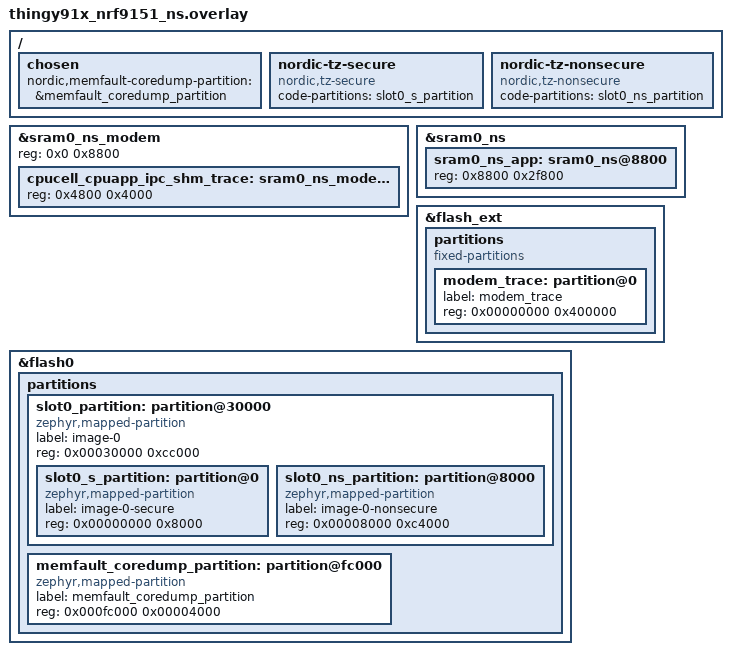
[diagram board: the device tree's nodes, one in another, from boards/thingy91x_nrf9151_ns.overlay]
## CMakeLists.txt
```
#
# Copyright (c) 2021 Nordic Semiconductor
#
# SPDX-License-Identifier: LicenseRef-Nordic-5-Clause
#

cmake_minimum_required(VERSION 3.20.0)

find_package(Zephyr REQUIRED HINTS $ENV{ZEPHYR_BASE})
project(memfault_sample)

# NORDIC SDK APP START
add_subdirectory(src)
# NORDIC SDK APP END

zephyr_include_directories(src)
zephyr_include_directories(config)
```

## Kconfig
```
#
# Copyright (c) 2021 Nordic Semiconductor ASA
#
# SPDX-License-Identifier: LicenseRef-Nordic-5-Clause
#

menu "Zephyr Kernel"
source "Kconfig.zephyr"
endmenu

module = MEMFAULT_SAMPLE
module-str = Memfault sample
source "$(ZEPHYR_BASE)/subsys/logging/Kconfig.template.log_config"
```

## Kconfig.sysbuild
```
#
# Copyright (c) 2024 Nordic Semiconductor
#
# SPDX-License-Identifier: LicenseRef-Nordic-5-Clause
#

config WIFI_NRF70
	default y if BOARD_NRF7002DK_NRF5340_CPUAPP

source "share/sysbuild/Kconfig"
```

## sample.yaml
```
sample:
  name: Memfault sample
tests:
  sample.debug.memfault:
    sysbuild: true
    build_only: true
    extra_configs:
      - CONFIG_MEMFAULT_NCS_PROJECT_KEY="dummy-key"
    integration_platforms:
      - nrf9151dk/nrf9151/ns
      - thingy91x/nrf9151/ns
      - nrf7002dk/nrf5340/cpuapp
    platform_allow:
      - nrf9160dk/nrf9160/ns
      - nrf9161dk/nrf9161/ns
      - nrf9151dk/nrf9151/ns
      - thingy91/nrf9160/ns
      - thingy91x/nrf9151/ns
      - nrf7002dk/nrf5340/cpuapp
    tags:
      - ci_build
      - sysbuild
      - ci_samples_debug
  sample.debug.memfault.etb:
    sysbuild: true
    build_only: true
    extra_configs:
      - CONFIG_MEMFAULT_NCS_PROJECT_KEY="dummy-key"
    extra_args: OVERLAY_CONFIG=overlay-etb.conf
    integration_platforms:
      - nrf9161dk/nrf9161/ns
      - nrf9151dk/nrf9151/ns
      - thingy91x/nrf9151/ns
    platform_allow:
      - nrf9160dk/nrf9160/ns
      - nrf9161dk/nrf9161/ns
      - nrf9151dk/nrf9151/ns
      - thingy91/nrf9160/ns
      - thingy91x/nrf9151/ns
    tags:
      - ci_build
      - sysbuild
      - ci_samples_debug
  # Split off from sample.debug.memfault.etb: ETB_TRACE depends on
  # SOC_SERIES_NRF91, so on the nRF5340 the whole ETB part of overlay-etb.conf
  # was silently dropped. This variant uses an overlay without it.
  sample.debug.memfault.etb.nrf53:
    sysbuild: true
    build_only: true
    extra_configs:
      - CONFIG_MEMFAULT_NCS_PROJECT_KEY="dummy-key"
    extra_args: OVERLAY_CONFIG=overlay-etb-nrf53.conf
    integration_platforms:
      - nrf7002dk/nrf5340/cpuapp
    platform_allow:
      - nrf7002dk/nrf5340/cpuapp
    tags:
      - ci_build
      - sysbuild
      - ci_samples_debug
  sample.debug.memfault.modem_trace_to_memfault:
    sysbuild: true
    build_only: true
    extra_configs:
      - CONFIG_MEMFAULT_NCS_PROJECT_KEY="dummy-key"
    extra_args: OVERLAY_CONFIG=overlay-modem-trace-to-memfault.conf
    integration_platforms:
      - nrf9151dk/nrf9151/ns
      - thingy91x/nrf9151/ns
    platform_allow:
      - nrf9151dk/nrf9151/ns
      - thingy91x/nrf9151/ns
    tags:
      - ci_build
      - sysbuild
      - ci_samples_debug
```

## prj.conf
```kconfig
#
# Copyright (c) 2021 Nordic Semiconductor ASA
#
# SPDX-License-Identifier: LicenseRef-Nordic-5-Clause
#

# General config
CONFIG_FPU=y
CONFIG_ASSERT=y

# Logging
CONFIG_LOG=y
CONFIG_LOG_BUFFER_SIZE=4096

# For more verbose and detailed log output, set the log level to
# CONFIG_MEMFAULT_SAMPLE_LOG_LEVEL_DBG=y instead.
CONFIG_MEMFAULT_SAMPLE_LOG_LEVEL_INF=y

# Network
CONFIG_NETWORKING=y
CONFIG_NET_NATIVE=y
CONFIG_NET_IPV4=y
CONFIG_NET_CONNECTION_MANAGER=y

# DK
CONFIG_DK_LIBRARY=y

# Memfault
CONFIG_MEMFAULT=y
CONFIG_MEMFAULT_PROJECT_KEY=""
CONFIG_MEMFAULT_SHELL=y
CONFIG_MEMFAULT_HTTP_PERIODIC_UPLOAD=y
CONFIG_MEMFAULT_LOGGING_ENABLE=y
CONFIG_MEMFAULT_LOGGING_RAM_SIZE=4096
CONFIG_MEMFAULT_LOG_LEVEL_DBG=y
CONFIG_MEMFAULT_NCS_STACK_METRICS=y
CONFIG_MEMFAULT_COREDUMP_FULL_THREAD_STACKS=y
CONFIG_MEMFAULT_HEAP_STATS=y

# Add to pick up support for sending Memfault data over HTTP
CONFIG_MEMFAULT_HTTP_ENABLE=y

# Store coredump to flash
CONFIG_MEMFAULT_NCS_LOG_LEVEL_DBG=y
CONFIG_MEMFAULT_NCS_INTERNAL_FLASH_BACKED_COREDUMP=y
CONFIG_MEMFAULT_COREDUMP_COLLECT_BSS_REGIONS=y

# Dependency for Memfaul shell
CONFIG_SHELL=y

# Dependencies for flash storage
CONFIG_FLASH=y
CONFIG_FLASH_MAP=y
CONFIG_STREAM_FLASH=y

# Heap and stacks
CONFIG_HEAP_MEM_POOL_SIZE=8192
CONFIG_MAIN_STACK_SIZE=8192
CONFIG_SYSTEM_WORKQUEUE_STACK_SIZE=2048
CONFIG_NET_CONNECTION_MANAGER_MONITOR_STACK_SIZE=1024
CONFIG_NET_MGMT_EVENT_STACK_SIZE=1024

# Memfault depends on POSIX, disable unneeded POSIX features
CONFIG_POSIX_FILE_SYSTEM=n
```

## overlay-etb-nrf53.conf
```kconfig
#
# Copyright (c) 2023 Nordic Semiconductor ASA
#
# SPDX-License-Identifier: LicenseRef-Nordic-5-Clause
#

# Variant of overlay-etb.conf for SoCs without an ETB. ETB_TRACE depends on
# SOC_SERIES_NRF91, and ETB_TRACE_LOW_POWER and MEMFAULT_NCS_ETB_CAPTURE depend
# on ETB_TRACE in turn, so those three settings cannot be applied here. Only the
# logging reduction is kept so the build stays comparable to the nRF91 one.
CONFIG_FAULT_DUMP=0
CONFIG_KERNEL_LOG_LEVEL_OFF=y
```

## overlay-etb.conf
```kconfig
#
# Copyright (c) 2023 Nordic Semiconductor ASA
#
# SPDX-License-Identifier: LicenseRef-Nordic-5-Clause
#

# ETB tracing
CONFIG_ETB_TRACE=y
CONFIG_ETB_TRACE_LOW_POWER=y
CONFIG_MEMFAULT_NCS_ETB_CAPTURE=y
# Reduce logging to avoid filling up ETB with data not related to the crash
CONFIG_FAULT_DUMP=0
CONFIG_KERNEL_LOG_LEVEL_OFF=y
```

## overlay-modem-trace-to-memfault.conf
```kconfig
#
# Copyright (c) 2025 Nordic Semiconductor ASA
#
# SPDX-License-Identifier: LicenseRef-Nordic-5-Clause
#

# Continuously store modem traces to flash and upload them to Memfault upon a coredump

# Memfault
CONFIG_MEMFAULT_NCS_POST_MODEM_TRACE_ON_COREDUMP=y

# nRF Modem lib trace
CONFIG_FCB=y
CONFIG_FLASH_MAP=y
CONFIG_NRF_MODEM_LIB_TRACE=y
# Set the default trace level to off preventing overwriting the trace leading up to the crash after
# boot. The Memfault LTE coredump modem trace layer will ensure that traces are enabled once
# the coredump/modem trace has been uploaded, or if there is no application coredump.
CONFIG_NRF_MODEM_LIB_TRACE_LEVEL_OFF=y
CONFIG_NRF_MODEM_LIB_SHELL_TRACE=y
CONFIG_NRF_MODEM_LIB_TRACE_BACKEND_FLASH=y
CONFIG_NRF_MODEM_TRACE_FLASH_NOSPACE_ERASE_OLDEST=y
CONFIG_NRF_MODEM_LIB_TRACE_STACK_SIZE=1024
# Maximum number of sectors that the trace backend can handle
CONFIG_NRF_MODEM_LIB_TRACE_FLASH_SECTORS=255
# Modem trace flash partition size with 255 sectors of 4kB each
CONFIG_NRF_MODEM_LIB_TRACE_BACKEND_FLASH_PARTITION_SIZE=0xFF000
```

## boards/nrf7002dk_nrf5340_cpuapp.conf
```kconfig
#
# Copyright (c) 2023 Nordic Semiconductor ASA
#
# SPDX-License-Identifier: LicenseRef-Nordic-5-Clause
#

# General
CONFIG_POSIX_TIMERS=y
CONFIG_HW_STACK_PROTECTION=y
CONFIG_HW_ID_LIBRARY=y
CONFIG_HW_ID_LIBRARY_SOURCE_NET_MAC=y

# Heap and stacks
CONFIG_HEAP_MEM_POOL_SIZE=153600
CONFIG_HEAP_MEM_POOL_SIZE=40144
CONFIG_NRF_WIFI_CTRL_HEAP_SIZE=15000
CONFIG_NRF_WIFI_DATA_HEAP_SIZE=98456
CONFIG_HEAP_MEM_POOL_IGNORE_MIN=y
CONFIG_SYSTEM_WORKQUEUE_STACK_SIZE=4096
CONFIG_MAIN_STACK_SIZE=8192
CONFIG_NET_TX_STACK_SIZE=4096
CONFIG_NET_RX_STACK_SIZE=4096
CONFIG_NET_CONNECTION_MANAGER_MONITOR_STACK_SIZE=4096

# Network and NET sockets
CONFIG_NET_L2_ETHERNET=y
CONFIG_NET_TCP=y
CONFIG_NET_UDP=y
CONFIG_NET_DHCPV4=y
CONFIG_NET_SOCKETS_OFFLOAD=n
CONFIG_NET_CONTEXT_SNDTIMEO=y
CONFIG_NET_CONTEXT_SYNC_RECV=y
CONFIG_NET_SOCKETS_ENABLE_DTLS=n
CONFIG_NET_SOCKETS_SOCKOPT_TLS=y
CONFIG_NET_SOCKETS=y
CONFIG_ZVFS_POLL_MAX=20
CONFIG_NET_STATISTICS=y
CONFIG_NET_STATISTICS_WIFI=y
CONFIG_NET_STATISTICS_USER_API=y
CONFIG_NET_PKT_RX_COUNT=8
CONFIG_NET_PKT_TX_COUNT=8
CONFIG_NET_MAX_CONTEXTS=5

# DNS
CONFIG_DNS_RESOLVER=y
CONFIG_NET_SOCKETS_DNS_TIMEOUT=30000

# printing of scan results puts pressure on queues in new locking
# design in net_mgmt. So, use a typical number of networks in a crowded
# environment as the queue depth.
CONFIG_NET_MGMT_EVENT_QUEUE_SIZE=150
CONFIG_NET_MGMT_EVENT_STACK_SIZE=4096

# Below section is the primary contributor to SRAM and is currently
# not optimized for size.
CONFIG_NET_BUF_RX_COUNT=16
CONFIG_NET_BUF_TX_COUNT=64
CONFIG_NET_BUF_DATA_SIZE=128
CONFIG_NET_TC_TX_COUNT=1

# Wi-Fi
CONFIG_WIFI=y
CONFIG_WIFI_NRF70=y
CONFIG_NET_L2_WIFI_SHELL=y
CONFIG_NET_SHELL=y
CONFIG_WIFI_CREDENTIALS=y

# Shell
CONFIG_SHELL=y
CONFIG_SHELL_STACK_SIZE=6144

# WPA
CONFIG_WIFI_NM_WPA_SUPPLICANT=y
CONFIG_WIFI_NM_WPA_SUPPLICANT_LOG_LEVEL_INF=y

# Settings subsystem
CONFIG_NVS=y
CONFIG_SETTINGS=y
CONFIG_SETTINGS_NVS=y

# mbedTLS
CONFIG_PSA_CRYPTO=y
CONFIG_MBEDTLS=y
CONFIG_MBEDTLS_ENABLE_HEAP=y
CONFIG_MBEDTLS_HEAP_SIZE=81920

# Memfault servers negotiate ECDHE-RSA when using MbedTLS 4.0
CONFIG_MBEDTLS_CIPHERSUITE_TLS_ECDHE_RSA_WITH_AES_128_GCM_SHA256=y
CONFIG_MBEDTLS_SSL_SERVER_NAME_INDICATION=y

# Certificate management
CONFIG_MEMFAULT_ROOT_CERT_STORAGE_TLS_CREDENTIAL_STORAGE=y
CONFIG_MEMFAULT_NCS_PROVISION_CERTIFICATES=y

# Zephyr NET Connection Manager Connectivity layer.
CONFIG_L2_WIFI_CONNECTIVITY=y
CONFIG_L2_WIFI_CONNECTIVITY_AUTO_CONNECT=n
CONFIG_L2_WIFI_CONNECTIVITY_AUTO_DOWN=n
```

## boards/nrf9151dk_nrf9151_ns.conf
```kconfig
#
# Copyright (c) 2024 Nordic Semiconductor ASA
#
# SPDX-License-Identifier: LicenseRef-Nordic-5-Clause
#

# TF-M
CONFIG_TFM_PROFILE_TYPE_MINIMAL=y

# Network
CONFIG_NET_SOCKETS=y
CONFIG_NET_SOCKETS_OFFLOAD=y

# Memfault
CONFIG_MEMFAULT_NCS_LTE_METRICS=y
CONFIG_MEMFAULT_NCS_POST_COREDUMP_ON_NETWORK_CONNECTED=y
CONFIG_LTE_LC_EDRX_MODULE=y
CONFIG_LTE_LC_PSM_MODULE=y

CONFIG_HW_ID_LIBRARY_SOURCE_IMEI=y
CONFIG_MODEM_INFO=y

# Certificate management
CONFIG_MEMFAULT_ROOT_CERT_STORAGE_NRF9160_MODEM=y
CONFIG_MODEM_KEY_MGMT=y

# AT command capability in shell
CONFIG_AT_SHELL=y
CONFIG_SHELL_WILDCARD=n

# Zephyr NET Connection Manager and Connectivity layer.
CONFIG_NRF_MODEM_LIB_NET_IF=y

# Disable Duplicate Address Detection (DAD)
# due to not being properly implemented for offloaded interfaces.
CONFIG_NET_IPV6_NBR_CACHE=n
CONFIG_NET_IPV6_MLD=n

# Enable SPI for External flash for storing modem traces that are uploaded to Memfault
CONFIG_SPI=y
CONFIG_SPI_NOR=y
CONFIG_SPI_NOR_SFDP_DEVICETREE=y
```

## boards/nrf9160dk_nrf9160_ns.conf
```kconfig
#
# Copyright (c) 2023 Nordic Semiconductor ASA
#
# SPDX-License-Identifier: LicenseRef-Nordic-5-Clause
#

# Network
CONFIG_NET_SOCKETS=y
CONFIG_NET_SOCKETS_OFFLOAD=y

# Memfault
CONFIG_MEMFAULT_NCS_LTE_METRICS=y
CONFIG_MEMFAULT_NCS_POST_COREDUMP_ON_NETWORK_CONNECTED=y
CONFIG_LTE_LC_EDRX_MODULE=y
CONFIG_LTE_LC_PSM_MODULE=y

CONFIG_HW_ID_LIBRARY_SOURCE_IMEI=y
CONFIG_MODEM_INFO=y

# Certificate management
CONFIG_MEMFAULT_ROOT_CERT_STORAGE_NRF9160_MODEM=y
CONFIG_MODEM_KEY_MGMT=y

# AT command capability in shell
CONFIG_AT_SHELL=y
CONFIG_SHELL_WILDCARD=n

# Zephyr NET Connection Manager and Connectivity layer.
CONFIG_NRF_MODEM_LIB_NET_IF=y

# Disable Duplicate Address Detection (DAD)
# due to not being properly implemented for offloaded interfaces.
CONFIG_NET_IPV6_NBR_CACHE=n
CONFIG_NET_IPV6_MLD=n
```

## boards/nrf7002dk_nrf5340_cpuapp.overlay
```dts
/*
 * Copyright (c) 2026 Nordic Semiconductor ASA
 *
 * SPDX-License-Identifier: LicenseRef-Nordic-5-Clause
 */

/ {
	chosen {
		nordic,memfault-coredump-partition = &memfault_coredump_partition;
	};
};

/delete-node/ &storage_partition;

&flash0 {
	partitions {
		storage_partition: partition@f8000 {
			compatible = "zephyr,mapped-partition";
			label = "storage";
			reg = <0x000f8000 0x00004000>;
		};

		memfault_coredump_partition: partition@fc000 {
			compatible = "zephyr,mapped-partition";
			label = "memfault_coredump_partition";
			reg = <0x000fc000 0x00004000>;
		};
	};
};
```

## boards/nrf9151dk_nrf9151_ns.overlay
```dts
/*
 * Copyright (c) 2025 Nordic Semiconductor ASA
 *
 * SPDX-License-Identifier: LicenseRef-Nordic-5-Clause
 */

#include <samples/cellular/nrf91_no_bootloader_partitions.dtsi>

#include <samples/cellular/nrf91_sram_partitions.dtsi>

/* Increase modem (shared) memory. */
&sram0_ns_modem {
	reg = <0x0 0x8800>;
	ranges = <0x0 0x0 0x8800>;

	cpucell_cpuapp_ipc_shm_trace: sram0_ns_modem@4800 {
		/* Modem trace memory */
		reg = <0x4800 0x4000>;
	};
};

/* Delete Non-Secure application memory so we can move and shrink it. */
/delete-node/ &sram0_ns_app;

&sram0_ns {
	sram0_ns_app: sram0_ns@8800 {
		/* Redefine smaller Non-Secure application memory. */
		reg = <0x8800 0x2f800>;
	};
};

&gd25wb256 {
	status = "okay";

	partitions {
		compatible = "fixed-partitions";
		#address-cells = <1>;
		#size-cells = <1>;

		modem_trace: partition@0 {
			label = "modem_trace";
			reg = <0x00000000 0x400000>;
		};
	};
};

/* The internal-flash coredump backend (CONFIG_MEMFAULT_NCS_INTERNAL_FLASH_BACKED_COREDUMP)
 * memory-maps the coredump partition and reads it with memcpy(), so it must live in
 * internal flash (not on the external gd25wb256). Carve it out of the storage region.
 */
/delete-node/ &storage_partition;

&flash0 {
	partitions {
		storage_partition: partition@f8000 {
			compatible = "zephyr,mapped-partition";
			label = "storage";
			reg = <0x000f8000 0x00004000>;
		};

		memfault_coredump_partition: partition@fc000 {
			compatible = "zephyr,mapped-partition";
			label = "memfault_coredump_partition";
			reg = <0x000fc000 0x00004000>;
		};
	};
};

/ {
	chosen {
		nordic,memfault-coredump-partition = &memfault_coredump_partition;
	};
};

/*
 * This layout redefines the flash partition map, dropping partitions that the
 * upstream nordic-tz-secure/-nonsecure descriptors reference. Remove the
 * descriptors so they do not hold dangling phandles (restores the behaviour
 * from before the descriptors were introduced).
 */
/ {
	/delete-node/ nordic-tz-secure;
	/delete-node/ nordic-tz-nonsecure;
};
```

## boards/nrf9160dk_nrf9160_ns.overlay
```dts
/*
 * Copyright (c) 2026 Nordic Semiconductor ASA
 *
 * SPDX-License-Identifier: LicenseRef-Nordic-5-Clause
 */

#include <samples/cellular/nrf91_no_bootloader_partitions.dtsi>

#include <samples/cellular/nrf91_sram_partitions.dtsi>

/* The internal-flash coredump backend (CONFIG_MEMFAULT_NCS_INTERNAL_FLASH_BACKED_COREDUMP)
 * memory-maps the coredump partition and reads it with memcpy(), so it must live in
 * internal flash (not on the external mx25r64). Carve it out of the storage region.
 */
/delete-node/ &storage_partition;

&flash0 {
	partitions {
		storage_partition: partition@f8000 {
			compatible = "zephyr,mapped-partition";
			label = "storage";
			reg = <0x000f8000 0x00004000>;
		};

		memfault_coredump_partition: partition@fc000 {
			compatible = "zephyr,mapped-partition";
			label = "memfault_coredump_partition";
			reg = <0x000fc000 0x00004000>;
		};
	};
};

/ {
	chosen {
		nordic,memfault-coredump-partition = &memfault_coredump_partition;
	};
};
```

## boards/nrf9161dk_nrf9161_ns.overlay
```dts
/*
 * Copyright (c) 2026 Nordic Semiconductor ASA
 *
 * SPDX-License-Identifier: LicenseRef-Nordic-5-Clause
 */

#include <samples/cellular/nrf91_no_bootloader_partitions.dtsi>

#include <samples/cellular/nrf91_sram_partitions.dtsi>

/* The internal-flash coredump backend (CONFIG_MEMFAULT_NCS_INTERNAL_FLASH_BACKED_COREDUMP)
 * memory-maps the coredump partition and reads it with memcpy(), so it must live in
 * internal flash (not on the external gd25wb256). Carve it out of the storage region.
 */
/delete-node/ &storage_partition;

&flash0 {
	partitions {
		storage_partition: partition@f8000 {
			compatible = "zephyr,mapped-partition";
			label = "storage";
			reg = <0x000f8000 0x00004000>;
		};

		memfault_coredump_partition: partition@fc000 {
			compatible = "zephyr,mapped-partition";
			label = "memfault_coredump_partition";
			reg = <0x000fc000 0x00004000>;
		};
	};
};

/ {
	chosen {
		nordic,memfault-coredump-partition = &memfault_coredump_partition;
	};
};

/*
 * This layout redefines the flash partition map, dropping partitions that the
 * upstream nordic-tz-secure/-nonsecure descriptors reference. Remove the
 * descriptors so they do not hold dangling phandles (restores the behaviour
 * from before the descriptors were introduced).
 */
/ {
	/delete-node/ nordic-tz-secure;
	/delete-node/ nordic-tz-nonsecure;
};
```

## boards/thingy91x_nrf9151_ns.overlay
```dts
/*
 * Copyright (c) 2025 Nordic Semiconductor ASA
 *
 * SPDX-License-Identifier: LicenseRef-Nordic-5-Clause
 */

/ {
	chosen {
		nordic,memfault-coredump-partition = &memfault_coredump_partition;
	};
};

/* Increase modem (shared) memory to add trace section. */
&sram0_ns_modem {
	reg = <0x0 0x8800>;
	ranges = <0x0 0x0 0x8800>;

	cpucell_cpuapp_ipc_shm_trace: sram0_ns_modem@4800 {
		/* Modem trace memory */
		reg = <0x4800 0x4000>;
	};
};

/* Delete Non-Secure application memory so we can move and shrink it. */
/delete-node/ &sram0_ns_app;

&sram0_ns {
	sram0_ns_app: sram0_ns@8800 {
		/* Redefine smaller Non-Secure application memory. */
		reg = <0x8800 0x2f800>;
	};
};

&flash_ext {
	partitions {
		compatible = "fixed-partitions";
		#address-cells = <1>;
		#size-cells = <1>;

		modem_trace: partition@0 {
			label = "modem_trace";
			reg = <0x00000000 0x400000>;
		};
	};
};

/* The internal-flash coredump backend (CONFIG_MEMFAULT_NCS_INTERNAL_FLASH_BACKED_COREDUMP)
 * memory-maps the coredump partition and reads it with memcpy(), so it must live in
 * internal flash (not on the external flash_ext). The internal flash is fully consumed
 * by slot0_partition, so shrink the non-secure image area by 16 kB to free space for the
 * coredump partition at the end of internal flash (mirrors the memfault-coredump snippet).
 */
/delete-node/ &slot0_partition;

&flash0 {
	partitions {
		slot0_partition: partition@30000 {
			compatible = "zephyr,mapped-partition";
			label = "image-0";
			reg = <0x00030000 0xcc000>;
			ranges = <0x0 0x00030000 0xcc000>;
			#address-cells = <1>;
			#size-cells = <1>;

			slot0_s_partition: partition@0 {
				compatible = "zephyr,mapped-partition";
				label = "image-0-secure";
				reg = <0x00000000 0x8000>;
			};

			slot0_ns_partition: partition@8000 {
				compatible = "zephyr,mapped-partition";
				label = "image-0-nonsecure";
				reg = <0x00008000 0xc4000>;
			};
		};

		memfault_coredump_partition: partition@fc000 {
			compatible = "zephyr,mapped-partition";
			label = "memfault_coredump_partition";
			reg = <0x000fc000 0x00004000>;
		};
	};
};

/ {
	/delete-node/ nordic-tz-secure;
	/delete-node/ nordic-tz-nonsecure;

	nordic-tz-secure {
		compatible = "nordic,tz-secure";
		code-partitions = <&slot0_s_partition>;
	};

	nordic-tz-nonsecure {
		compatible = "nordic,tz-nonsecure";
		code-partitions = <&slot0_ns_partition>;
	};
};
```

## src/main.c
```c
/*
 * Copyright (c) 2021 Nordic Semiconductor ASA
 *
 * SPDX-License-Identifier: LicenseRef-Nordic-5-Clause
 */

#include <zephyr/kernel.h>
#include <stdio.h>
#include <zephyr/net/conn_mgr_connectivity.h>
#include <zephyr/net/conn_mgr_monitor.h>
#include <memfault/metrics/metrics.h>
#include <memfault/ports/zephyr/http.h>
#include <memfault/core/data_packetizer.h>
#include <memfault/core/trace_event.h>
#include <memfault/panics/coredump.h>
#include <dk_buttons_and_leds.h>

#include <zephyr/logging/log.h>
#include <zephyr/logging/log_ctrl.h>

LOG_MODULE_REGISTER(memfault_sample, CONFIG_MEMFAULT_SAMPLE_LOG_LEVEL);

/* Macros used to subscribe to specific Zephyr NET management events. */
#define L4_EVENT_MASK	      (NET_EVENT_L4_CONNECTED | NET_EVENT_L4_DISCONNECTED)
#define CONN_LAYER_EVENT_MASK (NET_EVENT_CONN_IF_FATAL_ERROR)

static K_SEM_DEFINE(nw_connected_sem, 0, 1);

/* Zephyr NET management event callback structures. */
static struct net_mgmt_event_callback l4_cb;
static struct net_mgmt_event_callback conn_cb;

/* Recursive Fibonacci calculation used to trigger stack overflow. */
static int fib(int n)
{
	if (n <= 1) {
		return n;
	}

	return fib(n - 1) + fib(n - 2);
}

/* Handle button presses and trigger faults that can be captured and sent to
 * the Memfault cloud for inspection after rebooting:
 * Only button 1 is available on Thingy:91, the rest are available on nRF9160 DK.
 *	Button 1: Trigger stack overflow.
 *	Button 2: Trigger NULL-pointer dereference.
 *	Switch 1: Increment switch_1_toggle_count metric by one.
 *	Switch 2: Trace switch_2_toggled event, along with switch state.
 */
static void button_handler(uint32_t button_states, uint32_t has_changed)
{
	uint32_t buttons_pressed = has_changed & button_states;

	if (buttons_pressed & DK_BTN1_MSK) {
		LOG_WRN("Stack overflow will now be triggered");
		fib(10000);
	} else if (buttons_pressed & DK_BTN2_MSK) {
		volatile uint32_t i;

		LOG_WRN("Division by zero will now be triggered");
#pragma GCC diagnostic push
#pragma GCC diagnostic ignored "-Wdiv-by-zero"
		i = 1 / 0;
#pragma GCC diagnostic pop
		ARG_UNUSED(i);
	} else if (has_changed & DK_BTN3_MSK) {
		/* DK_BTN3_MSK is Switch 1 on nRF9160 DK. */
		int err = MEMFAULT_METRIC_ADD(switch_1_toggle_count, 1);
		if (err) {
			LOG_ERR("Failed to increment switch_1_toggle_count");
		} else {
			LOG_INF("switch_1_toggle_count incremented");
		}
	} else if (has_changed & DK_BTN4_MSK) {
		/* DK_BTN4_MSK is Switch 2 on nRF9160 DK. */
		MEMFAULT_TRACE_EVENT_WITH_LOG(switch_2_toggled, "Switch state: %d",
					      buttons_pressed & DK_BTN4_MSK ? 1 : 0);
		LOG_INF("switch_2_toggled event has been traced, button state: %d",
			buttons_pressed & DK_BTN4_MSK ? 1 : 0);
	}
}

static void on_connect(void)
{
#if IS_ENABLED(MEMFAULT_NCS_LTE_METRICS)
	uint32_t time_to_lte_connection;

	/* Retrieve the LTE time to connect metric. */
	memfault_metrics_heartbeat_timer_read(MEMFAULT_METRICS_KEY(ncs_lte_time_to_connect_ms),
					      &time_to_lte_connection);

	LOG_INF("Time to connect: %d ms", time_to_lte_connection);
#endif /* IS_ENABLED(MEMFAULT_NCS_LTE_METRICS) */

	if (IS_ENABLED(CONFIG_MEMFAULT_NCS_POST_COREDUMP_ON_NETWORK_CONNECTED) &&
	    memfault_coredump_has_valid_coredump(NULL)) {
		/* Coredump sending handled internally */
		return;
	}

	LOG_INF("Sending already captured data to Memfault");

	/* Trigger collection of heartbeat data. */
	memfault_metrics_heartbeat_debug_trigger();

	/* Check if there is any data available to be sent. */
	if (!memfault_packetizer_data_available()) {
		LOG_DBG("There was no data to be sent");
		return;
	}

	LOG_DBG("Sending stored data...");

	/* Send the data that has been captured to the memfault cloud.
	 * This will also happen periodically, with an interval that can be configured using
	 * CONFIG_MEMFAULT_HTTP_PERIODIC_UPLOAD_INTERVAL_SECS.
	 */
	memfault_zephyr_port_post_data();
}

static void l4_event_handler(struct net_mgmt_event_callback *cb, uint64_t event,
			     struct net_if *iface)
{
	switch (event) {
	case NET_EVENT_L4_CONNECTED:
		LOG_INF("Network connectivity established");
		k_sem_give(&nw_connected_sem);
		break;
	case NET_EVENT_L4_DISCONNECTED:
		LOG_INF("Network connectivity lost");
		break;
	default:
		LOG_DBG("Unknown event: 0x%08llX", event);
		return;
	}
}

static void connectivity_event_handler(struct net_mgmt_event_callback *cb, uint64_t event,
				       struct net_if *iface)
{
	if (event == NET_EVENT_CONN_IF_FATAL_ERROR) {
		__ASSERT(false, "Failed to connect to a network");
		return;
	}
}

int main(void)
{
	int err;

	LOG_INF("Memfault sample has started");

	err = dk_buttons_init(button_handler);
	if (err) {
		LOG_ERR("dk_buttons_init, error: %d", err);
	}
	/* Setup handler for Zephyr NET Connection Manager events. */
	net_mgmt_init_event_callback(&l4_cb, l4_event_handler, L4_EVENT_MASK);
	net_mgmt_add_event_callback(&l4_cb);

	/* Setup handler for Zephyr NET Connection Manager Connectivity layer. */
	net_mgmt_init_event_callback(&conn_cb, connectivity_event_handler, CONN_LAYER_EVENT_MASK);
	net_mgmt_add_event_callback(&conn_cb);

	/* Connecting to the configured connectivity layer.
	 * Wi-Fi or LTE depending on the board that the sample was built for.
	 */
	LOG_INF("Bringing network interface up and connecting to the network");

	err = conn_mgr_all_if_up(true);
	if (err) {
		__ASSERT(false, "conn_mgr_all_if_up, error: %d", err);
		return err;
	}

	err = conn_mgr_all_if_connect(true);
	if (err) {
		__ASSERT(false, "conn_mgr_all_if_connect, error: %d", err);
		return err;
	}

	/* Performing in an infinite loop to be resilient against
	 * re-connect bursts directly after boot, e.g. when connected
	 * to a roaming network or via weak signal. Note that
	 * Memfault data will be uploaded periodically every
	 * CONFIG_MEMFAULT_HTTP_PERIODIC_UPLOAD_INTERVAL_SECS.
	 * We post data here so as soon as a connection is available
	 * the latest data will be pushed to Memfault.
	 */

	while (1) {
		k_sem_take(&nw_connected_sem, K_FOREVER);
		LOG_INF("Connected to network");
		on_connect();
	}
}
```

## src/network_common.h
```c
/*
 * Copyright (c) 2023 Nordic Semiconductor ASA
 *
 * SPDX-License-Identifier: LicenseRef-Nordic-5-Clause
 */

/**
 * @brief Initialize the network interface and establish a network connection.
 *
 */
void network_init(void);

/**
 * @brief A function to be called when the network connection has been established and IP address
 *        received. The application can establish a TCP connection when this function is called by
 *        the network implementation.
 */
void network_connected(void);

/**
 * @brief A function to be called when the network connection has been terminated.
 */
void network_disconnected(void);
```

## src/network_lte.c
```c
/*
 * Copyright (c) 2023 Nordic Semiconductor ASA
 *
 * SPDX-License-Identifier: LicenseRef-Nordic-5-Clause
 */

#include <zephyr/kernel.h>
#include <zephyr/logging/log.h>
#include <modem/nrf_modem_lib.h>
#include <modem/pdn.h>
#include <modem/lte_lc.h>

#include "network_common.h"

LOG_MODULE_REGISTER(network, CONFIG_MEMFAULT_SAMPLE_LOG_LEVEL);

/* Handler that is used to notify the application about LTE link specific events. */
static void lte_event_handler(const struct lte_lc_evt *const evt)
{
	if ((evt->type == LTE_LC_EVT_MODEM_EVENT) &&
	    (evt->modem_evt == LTE_LC_MODEM_EVT_RESET_LOOP)) {
		LOG_WRN("The modem has detected a reset loop.");
		LOG_WRN("LTE network attach is now "
			"restricted for the next 30 minutes.");
		LOG_WRN("Power-cycle the device to "
			"circumvent this restriction.");
		LOG_WRN("For more information see the nRF91 AT Commands - Command "
			"Reference Guide v2.0 - chpt. 5.36");
	}
}

/* Handler that notifies the application of events related to the default PDN context, CID 0. */
void pdn_event_handler(uint8_t cid, enum pdn_event event, int reason)
{
	ARG_UNUSED(cid);

	switch (event) {
	case PDN_EVENT_CNEC_ESM:
		LOG_DBG("Event: PDP context %d, %s", cid, pdn_esm_strerror(reason));
		return;
	case PDN_EVENT_ACTIVATED:
		LOG_INF("PDN connection activated");
		network_connected();
		break;
	case PDN_EVENT_DEACTIVATED:
		LOG_INF("PDN connection deactivated");
		network_disconnected();
		break;
	case PDN_EVENT_IPV6_UP:
		LOG_DBG("PDN_EVENT_IPV6_UP");
		return;
	case PDN_EVENT_IPV6_DOWN:
		LOG_DBG("PDN_EVENT_IPV6_DOWN");
		return;
	default:
		LOG_ERR("Unexpected PDN event: %d", event);
		return;
	}
}

static void modem_configure(void)
{
	int err;

	err = nrf_modem_lib_init();
	if (err) {
		LOG_ERR("Modem library could not be initialized, err %d", err);
		return;
	}

	/* Setup a callback for the default PDP context. */
	err = pdn_default_ctx_cb_reg(pdn_event_handler);

	if (err) {
		LOG_ERR("pdn_default_ctx_cb_reg, error: %d", err);
		return;
	}

	/* Register handler to receive LTE link specific events. */
	lte_lc_register_handler(lte_event_handler);

	/* Subscribe to modem domain events (AT%MDMEV).
	 * Modem domain events is received in the lte_event_handler().
	 *
	 * This function fails for modem firmware versions < 1.3.0 due to not being supported.
	 * Therefore we ignore its return value.
	 */
	(void)lte_lc_modem_events_enable();

	LOG_INF("Connecting to LTE network...");

	/* Initialize the link controller and connect to LTE network. */
	err = lte_lc_init_and_connect();
	if (err) {
		LOG_ERR("lte_lc_init_and_connect, error: %d", err);
	}
}

void network_init(void)
{
	modem_configure();

}
```

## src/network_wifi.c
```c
/*
 * Copyright (c) 2023 Nordic Semiconductor ASA
 *
 * SPDX-License-Identifier: LicenseRef-Nordic-5-Clause
 */

#include <zephyr/kernel.h>
#include <zephyr/logging/log.h>
#include <zephyr/net/net_if.h>
#include <zephyr/net/wifi_mgmt.h>
#include <zephyr/net/net_event.h>
#include <net/wifi_mgmt_ext.h>
#include <modem/lte_lc.h>

#include "network_common.h"

LOG_MODULE_REGISTER(network, CONFIG_MEMFAULT_SAMPLE_LOG_LEVEL);

#define MGMT_EVENTS (NET_EVENT_WIFI_CONNECT_RESULT | NET_EVENT_WIFI_DISCONNECT_RESULT)

static struct net_mgmt_event_callback net_mgmt_callback;
static struct net_mgmt_event_callback net_mgmt_ipv4_callback;

static void connect(void)
{
	struct net_if *iface = net_if_get_default();

	if (iface == NULL) {
		LOG_ERR("Returned network interface is NULL");
		return;
	}

	int err = net_mgmt(NET_REQUEST_WIFI_CONNECT_STORED, iface, NULL, 0);

	if (err) {
		LOG_ERR("Connecting to Wi-Fi failed. error: %d", err);
	}
}

static void wifi_mgmt_event_handler(struct net_mgmt_event_callback *cb,
				    uint32_t mgmt_event, struct net_if *iface)
{
	const struct wifi_status *wifi_status = (const struct wifi_status *)cb->info;

	switch (mgmt_event) {
	case NET_EVENT_WIFI_CONNECT_RESULT:
		if (wifi_status->status) {
			LOG_INF("Connection attempt failed, status code: %d", wifi_status->status);
			return;
		}

		LOG_INF("Wi-Fi Connected, waiting for IP address");

		return;
	case NET_EVENT_WIFI_DISCONNECT_RESULT:
		LOG_INF("Disconnected");
		network_disconnected();
		break;
	default:
		LOG_ERR("Unknown event: %d", mgmt_event);
		return;
	}
}

static void ipv4_mgmt_event_handler(struct net_mgmt_event_callback *cb,
				    uint32_t event, struct net_if *iface)
{
	switch (event) {
	case NET_EVENT_IPV4_ADDR_ADD:
		LOG_INF("IPv4 address acquired");
		network_connected();
		break;
	case NET_EVENT_IPV4_ADDR_DEL:
		LOG_INF("IPv4 address lost");
		network_disconnected();
		break;
	default:
		LOG_DBG("Unknown event: 0x%08X", event);
		return;
	}
}

void network_init(void)
{
	net_mgmt_init_event_callback(&net_mgmt_callback, wifi_mgmt_event_handler, MGMT_EVENTS);
	net_mgmt_add_event_callback(&net_mgmt_callback);
	net_mgmt_init_event_callback(&net_mgmt_ipv4_callback, ipv4_mgmt_event_handler,
				     NET_EVENT_IPV4_ADDR_ADD | NET_EVENT_IPV4_ADDR_DEL);
	net_mgmt_add_event_callback(&net_mgmt_ipv4_callback);

	/* Add temporary fix to prevent using Wi-Fi before WPA supplicant is ready. */
	k_sleep(K_SECONDS(1));

	if (IS_ENABLED(CONFIG_WIFI_CREDENTIALS_STATIC)) {
		connect();
	}
}
```
